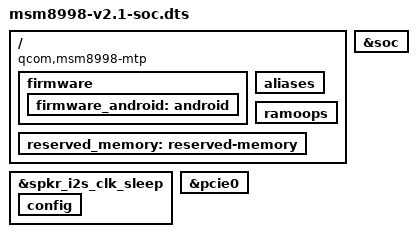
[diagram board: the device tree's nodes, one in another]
/* Copyright (c) 2016, The Linux Foundation. All rights reserved.
 *
 * This program is free software; you can redistribute it and/or modify
 * it under the terms of the GNU General Public License version 2 and
 * only version 2 as published by the Free Software Foundation.
 *
 * This program is distributed in the hope that it will be useful,
 * but WITHOUT ANY WARRANTY; without even the implied warranty of
 * MERCHANTABILITY or FITNESS FOR A PARTICULAR PURPOSE.  See the
 * GNU General Public License for more details.
 */

/dts-v1/;

#include "../qcom/msm8998-v2.1.dtsi"
/ {
	compatible = "qcom,msm8998-mtp", "qcom,msm8998", "qcom,mtp";
	firmware {
		firmware_android: android {};
	};
};

/ {
	aliases: aliases {};
	ramoops: ramoops {};
	reserved_memory: reserved-memory {};
};

&spkr_i2s_clk_sleep {
	config {
		/delete-property/ bias-pull-down;
	};
};

&soc {
	/delete-node/ qcom,qbt1000;
};

&pcie0 {
	/delete-property/ qcom,l1ss-supported;
};
